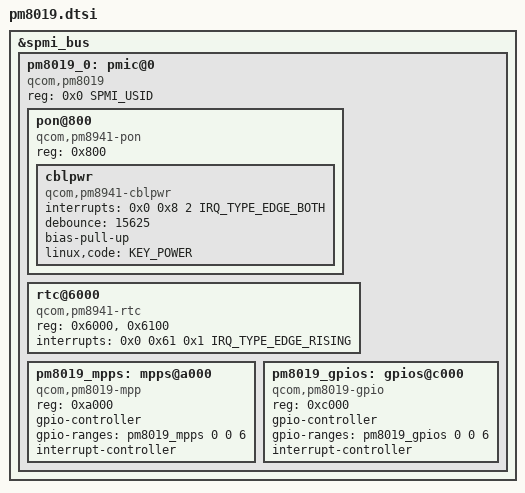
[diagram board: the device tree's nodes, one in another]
// SPDX-License-Identifier: GPL-2.0-only
#include <dt-bindings/spmi/spmi.h>
#include <dt-bindings/interrupt-controller/irq.h>
#include <dt-bindings/input/input.h>

&spmi_bus {
	pm8019_0: pmic@0 {
		compatible = "qcom,pm8019", "qcom,spmi-pmic";
		reg = <0x0 SPMI_USID>;
		#address-cells = <1>;
		#size-cells = <0>;

		pon@800 {
			compatible = "qcom,pm8941-pon";
			reg = <0x800>;

			cblpwr {
				compatible = "qcom,pm8941-cblpwr";
				interrupts = <0x0 0x8 2 IRQ_TYPE_EDGE_BOTH>;
				debounce = <15625>;
				bias-pull-up;
				linux,code = <KEY_POWER>;
			};
		};

		rtc@6000 {
			compatible = "qcom,pm8941-rtc";
			reg = <0x6000>, <0x6100>;
			reg-names = "rtc", "alarm";
			interrupts = <0x0 0x61 0x1 IRQ_TYPE_EDGE_RISING>;
		};

		pm8019_mpps: mpps@a000 {
			compatible = "qcom,pm8019-mpp", "qcom,spmi-mpp";
			reg = <0xa000>;
			gpio-controller;
			#gpio-cells = <2>;
			gpio-ranges = <&pm8019_mpps 0 0 6>;
			interrupt-controller;
			#interrupt-cells = <2>;
		};

		pm8019_gpios: gpios@c000 {
			compatible = "qcom,pm8019-gpio", "qcom,spmi-gpio";
			reg = <0xc000>;
			gpio-controller;
			gpio-ranges = <&pm8019_gpios 0 0 6>;
			#gpio-cells = <2>;
			interrupt-controller;
			#interrupt-cells = <2>;
		};
	};
};
